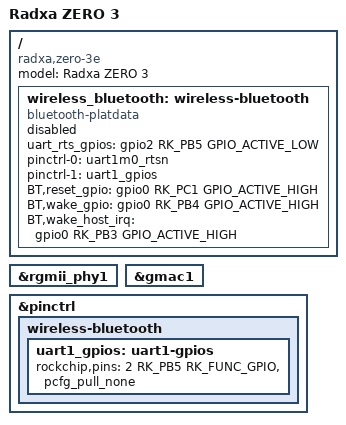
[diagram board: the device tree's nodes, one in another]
// SPDX-License-Identifier: (GPL-2.0+ OR MIT)
/*
 * Copyright (c) 2024 Rockchip Electronics Co., Ltd.
 * Copyright (c) 2025 Radxa Computer (Shenzhen) Co., Ltd.
 *
 */

/dts-v1/;

#include "rk3566-radxa-zero3.dtsi"

/ {
	model = "Radxa ZERO 3";
	compatible = "radxa,zero-3e", "radxa,zero3", "rockchip,rk3566";

	wireless_bluetooth: wireless-bluetooth {
		compatible = "bluetooth-platdata";
		uart_rts_gpios = <&gpio2 RK_PB5 GPIO_ACTIVE_LOW>;
		pinctrl-names = "default", "rts_gpio";
		pinctrl-0 = <&uart1m0_rtsn>;
		pinctrl-1 = <&uart1_gpios>;
		BT,reset_gpio    = <&gpio0 RK_PC1 GPIO_ACTIVE_HIGH>;
		BT,wake_gpio     = <&gpio0 RK_PB4 GPIO_ACTIVE_HIGH>;
		BT,wake_host_irq = <&gpio0 RK_PB3 GPIO_ACTIVE_HIGH>;
		status = "disabled";
	};
};

&rgmii_phy1 {
	status = "okay";
};

&gmac1 {
	status = "okay";
};

&pinctrl {
	wireless-bluetooth {
		uart1_gpios: uart1-gpios {
			rockchip,pins = <2 RK_PB5 RK_FUNC_GPIO &pcfg_pull_none>;
		};
	};
};
